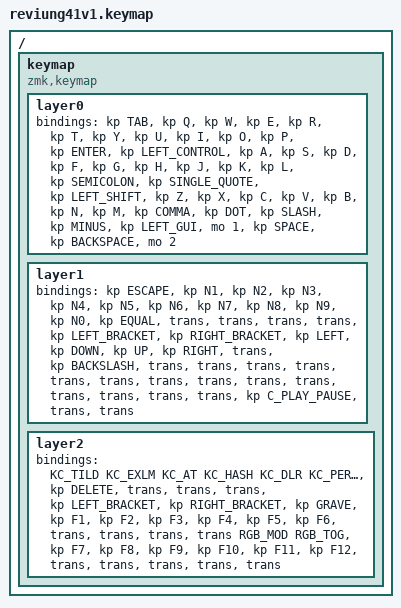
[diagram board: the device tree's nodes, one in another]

  /*
  * Copyright (c) 2020 The ZMK Contributors
  *
  * SPDX-License-Identifier: MIT
  */

  #include <behaviors.dtsi>
  #include <dt-bindings/zmk/keys.h>
  #include <dt-bindings/zmk/bt.h>
  #include <dt-bindings/zmk/rgb.h>

  / {
    keymap {
      compatible = "zmk,keymap";
  layer0 {
          bindings = <
          &kp TAB &kp Q &kp W &kp E &kp R &kp T &kp Y &kp U &kp I &kp O &kp P &kp ENTER &kp LEFT_CONTROL &kp A &kp S &kp D &kp F &kp G &kp H &kp J &kp K &kp L &kp SEMICOLON &kp SINGLE_QUOTE &kp LEFT_SHIFT &kp Z &kp X &kp C &kp V &kp B &kp N &kp M &kp COMMA &kp DOT &kp SLASH &kp MINUS &kp LEFT_GUI &mo 1 &kp SPACE &kp BACKSPACE &mo 2
          >;
        };layer1 {
          bindings = <
          &kp ESCAPE &kp N1 &kp N2 &kp N3 &kp N4 &kp N5 &kp N6 &kp N7 &kp N8 &kp N9 &kp N0 &kp EQUAL &trans &trans &trans &trans &kp LEFT_BRACKET &kp RIGHT_BRACKET &kp LEFT &kp DOWN &kp UP &kp RIGHT &trans &kp BACKSLASH &trans &trans &trans &trans &trans &trans &trans &trans &trans &trans &trans &trans &trans &trans &kp C_PLAY_PAUSE &trans &trans
          >;
        };layer2 {
          bindings = <
          KC_TILD KC_EXLM KC_AT KC_HASH KC_DLR KC_PERC KC_CIRC KC_AMPR KC_ASTR KC_LPRN KC_RPRN &kp DELETE &trans &trans &trans &kp LEFT_BRACKET &kp RIGHT_BRACKET &kp GRAVE &kp F1 &kp F2 &kp F3 &kp F4 &kp F5 &kp F6 &trans &trans &trans &trans RGB_MOD RGB_TOG &kp F7 &kp F8 &kp F9 &kp F10 &kp F11 &kp F12 &trans &trans &trans &trans &trans
          >;
        };
    };
  };
  
